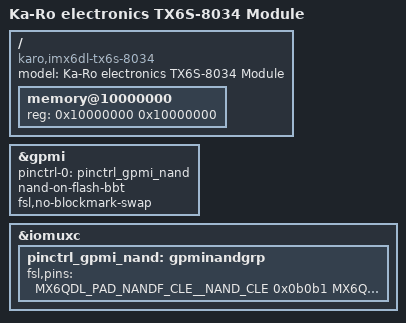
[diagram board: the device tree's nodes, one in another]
// SPDX-License-Identifier: GPL-2.0+
/*
 * Copyright (C) 2026 Ka-Ro Electronics GmbH
 * Ka-Ro TX6S-8034 module (i.MX6S, 256 MiB DDR3, 128 MiB NAND)
 */

/dts-v1/;

#include "imx6dl.dtsi"
#include "imx6qdl-tx6.dtsi"

/ {
	model = "Ka-Ro electronics TX6S-8034 Module";
	compatible = "karo,imx6dl-tx6s-8034", "karo,imx6dl-tx6s", "fsl,imx6dl";

	memory@10000000 {
		device_type = "memory";
		reg = <0x10000000 0x10000000>; /* 256 MiB */
	};
};

&gpmi {
	pinctrl-names = "default";
	pinctrl-0 = <&pinctrl_gpmi_nand>;
	nand-on-flash-bbt;
	fsl,no-blockmark-swap;
	status = "okay";
};

&iomuxc {
	pinctrl_gpmi_nand: gpminandgrp {
		fsl,pins = <
			MX6QDL_PAD_NANDF_CLE__NAND_CLE		0x0b0b1
			MX6QDL_PAD_NANDF_ALE__NAND_ALE		0x0b0b1
			MX6QDL_PAD_NANDF_WP_B__NAND_WP_B	0x0b0b1
			MX6QDL_PAD_NANDF_RB0__NAND_READY_B	0x0b000
			MX6QDL_PAD_NANDF_CS0__NAND_CE0_B	0x0b0b1
			MX6QDL_PAD_SD4_CMD__NAND_RE_B		0x0b0b1
			MX6QDL_PAD_SD4_CLK__NAND_WE_B		0x0b0b1
			MX6QDL_PAD_NANDF_D0__NAND_DATA00	0x0b0b1
			MX6QDL_PAD_NANDF_D1__NAND_DATA01	0x0b0b1
			MX6QDL_PAD_NANDF_D2__NAND_DATA02	0x0b0b1
			MX6QDL_PAD_NANDF_D3__NAND_DATA03	0x0b0b1
			MX6QDL_PAD_NANDF_D4__NAND_DATA04	0x0b0b1
			MX6QDL_PAD_NANDF_D5__NAND_DATA05	0x0b0b1
			MX6QDL_PAD_NANDF_D6__NAND_DATA06	0x0b0b1
			MX6QDL_PAD_NANDF_D7__NAND_DATA07	0x0b0b1
		>;
	};
};
